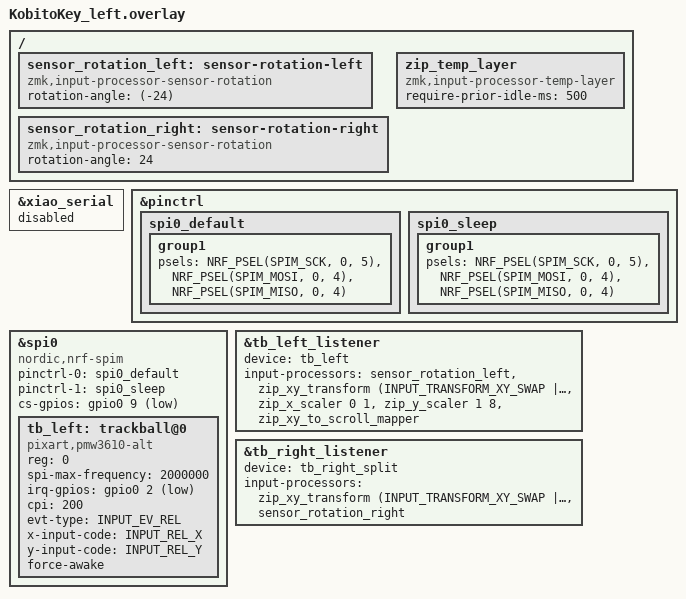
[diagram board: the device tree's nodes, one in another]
#include "kobitokey.dtsi"
#include <zephyr/dt-bindings/input/input-event-codes.h>
#include <input/processors.dtsi>
#include <input/processors/sensor_rotation.dtsi>

&xiao_serial { status = "disabled"; };
&pinctrl {
    spi0_default: spi0_default {
        group1 {
            psels = <NRF_PSEL(SPIM_SCK,  0, 5)>,
                    <NRF_PSEL(SPIM_MOSI, 0, 4)>,
                    <NRF_PSEL(SPIM_MISO, 0, 4)>;
        };
    };
    spi0_sleep: spi0_sleep {
        group1 {
            psels = <NRF_PSEL(SPIM_SCK,  0, 5)>,
                    <NRF_PSEL(SPIM_MOSI, 0, 4)>,
                    <NRF_PSEL(SPIM_MISO, 0, 4)>;
        };
    };
};

&spi0 {
    status = "okay";
    compatible = "nordic,nrf-spim";
    pinctrl-0 = <&spi0_default>;
    pinctrl-1 = <&spi0_sleep>;
    pinctrl-names = "default", "sleep";
    cs-gpios = <&gpio0 9 GPIO_ACTIVE_LOW>;

tb_left: trackball@0 {
        status = "okay";
        compatible = "pixart,pmw3610-alt"; /* 💡 alt に変更 */
        reg = <0>;
        spi-max-frequency = <2000000>;
        
        irq-gpios = <&gpio0 2 (GPIO_ACTIVE_LOW | GPIO_PULL_UP)>;
        cpi = <200>; /* 💡 スクロール用なので200〜400の低めでOKです */
        
        evt-type = <INPUT_EV_REL>;
        x-input-code = <INPUT_REL_X>;
        y-input-code = <INPUT_REL_Y>;
        
        force-awake;
    };
};

/ {
    sensor_rotation_left: sensor-rotation-left {
        compatible = "zmk,input-processor-sensor-rotation";
        status = "okay";
        #input-processor-cells = <0>;
        rotation-angle = <(-24)>;
    };
    sensor_rotation_right: sensor-rotation-right {
        compatible = "zmk,input-processor-sensor-rotation";
        #input-processor-cells = <0>;
        status = "okay";
        rotation-angle = <24>;
    };
};

&tb_left_listener {
    status = "okay";
    device = <&tb_left>;
    input-processors =
        <&sensor_rotation_left>,
        
        /* ✨ ここを追加：スクロールマッパーに通す前に、右手側で大成功した設定を挟んで生の向きを完全に正常化します */
        <&zip_xy_transform (INPUT_TRANSFORM_XY_SWAP | INPUT_TRANSFORM_Y_INVERT)>,
        
        <&zip_x_scaler 0 1>,
        <&zip_y_scaler 1 8>,
        <&zip_xy_to_scroll_mapper>;
        
        /* ❌ 古い &zip_scroll_transform の行はクラッシュの原因になるため完全に削除しました */
};

/ {
  /omit-if-no-ref/ zip_temp_layer: zip_temp_layer {
    compatible = "zmk,input-processor-temp-layer";
    #input-processor-cells = <2>;
    require-prior-idle-ms = <500>;
  };
};

&tb_right_listener {
    status = "okay";
    device = <&tb_right_split>;
    
    input-processors = 
        /* 1. まず全ての変換（縦横入れ替え・上下反転・左右反転）をここで一気に終わらせます */
        <&zip_xy_transform (INPUT_TRANSFORM_XY_SWAP | INPUT_TRANSFORM_Y_INVERT | INPUT_TRANSFORM_X_INVERT)>,
        
        /* 2. 画面と100%一致した軸に対して、最後に角度の微調整をかけます */
        <&sensor_rotation_right>;
};

/* &zip_temp_layer {
    excluded-positions = <
        1  2  3  6  7  8  14  15  31  32  34  35  36  39
    >;
}; */
